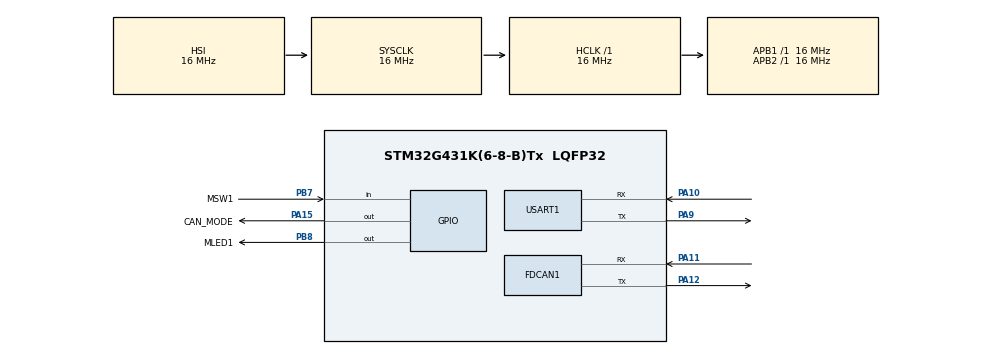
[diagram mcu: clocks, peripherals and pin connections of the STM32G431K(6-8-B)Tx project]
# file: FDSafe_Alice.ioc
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FDCAN1.CalculateBaudRateNominal=2000000
FDCAN1.CalculateTimeBitNominal=500
FDCAN1.CalculateTimeQuantumNominal=62.5
FDCAN1.DataSyncJumpWidth=2
FDCAN1.DataTimeSeg1=5
FDCAN1.DataTimeSeg2=2
FDCAN1.FrameFormat=FDCAN_FRAME_FD_NO_BRS
FDCAN1.NominalPrescaler=1
FDCAN1.NominalSyncJumpWidth=2
FDCAN1.NominalTimeSeg1=5
FDCAN1.NominalTimeSeg2=2
Mcu.Family=STM32G4
Mcu.Name=STM32G431K(6-8-B)Tx
Mcu.Package=LQFP32
NVIC.PriorityGroup=NVIC_PRIORITYGROUP_4
PA10.Mode=Asynchronous
PA10.Signal=USART1_RX
PA11.Mode=FDCAN_Activate
PA11.Signal=FDCAN1_RX
PA12.Mode=FDCAN_Activate
PA12.Signal=FDCAN1_TX
PA15.GPIO_Label=CAN_MODE
PA15.Signal=GPIO_Output
PA9.Mode=Asynchronous
PA9.Signal=USART1_TX
PB7.GPIO_Label=MSW1
PB7.GPIO_PuPd=GPIO_PULLUP
PB7.Signal=GPIO_Input
PB8-BOOT0.GPIO_Label=MLED1
PB8-BOOT0.PinState=GPIO_PIN_SET
PB8-BOOT0.Signal=GPIO_Output
ProjectManager.HeapSize=0x200
ProjectManager.StackSize=0x400
ProjectManager.TargetToolchain=STM32CubeIDE
RCC.AHBFreq_Value=16000000
RCC.APB1Freq_Value=16000000
RCC.APB1TimFreq_Value=16000000
RCC.APB2Freq_Value=16000000
RCC.APB2TimFreq_Value=16000000
RCC.CortexFreq_Value=16000000
RCC.EXTERNAL_CLOCK_VALUE=12288000
RCC.HCLKFreq_Value=16000000
RCC.HSE_VALUE=8000000
RCC.HSI48_VALUE=48000000
RCC.HSI_VALUE=16000000
RCC.LSE_VALUE=32768
RCC.PLLN=12
RCC.PLLQ=RCC_PLLQ_DIV4
RCC.SYSCLKFreq_VALUE=16000000
RCC.USBFreq_Value=48000000
RCC.VCOOutputFreq_Value=192000000
USART1.VirtualMode-Asynchronous=VM_ASYNC
VP_CRC_VS_CRC.Mode=CRC_Activate
VP_RNG_VS_RNG.Mode=RNG_Activate
VP_SYS_VS_DBSignals.Mode=DisableDeadBatterySignals
board=custom

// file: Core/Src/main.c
/* USER CODE BEGIN Header */
/**
 ******************************************************************************
 * @file           : main.c
 * @brief          : Main program body
 ******************************************************************************
 * @attention
 *
 * Copyright (c) 2024 STMicroelectronics.
 * All rights reserved.
 *
 * This software is licensed under terms that can be found in the LICENSE file
 * in the root directory of this software component.
 * If no LICENSE file comes with this software, it is provided AS-IS.
 *
 ******************************************************************************
 */
/* USER CODE END Header */
#include "main.h"

/* USER CODE BEGIN PD */

//#define PUTCHAR_PROTOTYPE int __io_putchar(int ch)
/* USER CODE END PD */

CRC_HandleTypeDef hcrc;

FDCAN_HandleTypeDef hfdcan1;

RNG_HandleTypeDef hrng;

UART_HandleTypeDef huart1;

void SystemClock_Config(void);
static void MX_GPIO_Init(void);
static void MX_FDCAN1_Init(void);
static void MX_USART1_UART_Init(void);
static void MX_RNG_Init(void);
static void MX_CRC_Init(void);

int main(void)
{

  /* MCU Configuration--------------------------------------------------------*/

  /* Reset of all peripherals, Initializes the Flash interface and the Systick. */
  HAL_Init();

  /* Configure the system clock */
  SystemClock_Config();

  /* Initialize all configured peripherals */
  MX_GPIO_Init();
  MX_FDCAN1_Init();
  MX_USART1_UART_Init();
  MX_RNG_Init();
  MX_CRC_Init();
  /* USER CODE BEGIN 2 */

	fdsafe_setup();

  /* USER CODE END 2 */

  /* Infinite loop */
  /* USER CODE BEGIN WHILE */
	while (1)
	{
		fdsafe_main();

    /* USER CODE END WHILE */

	}
}

void SystemClock_Config(void)
{
  RCC_OscInitTypeDef RCC_OscInitStruct = {0};
  RCC_ClkInitTypeDef RCC_ClkInitStruct = {0};

  /** Configure the main internal regulator output voltage
  */
  HAL_PWREx_ControlVoltageScaling(PWR_REGULATOR_VOLTAGE_SCALE1);

  /** Initializes the RCC Oscillators according to the specified parameters
  * in the RCC_OscInitTypeDef structure.
  */
  RCC_OscInitStruct.OscillatorType = RCC_OSCILLATORTYPE_HSI;
  RCC_OscInitStruct.HSIState = RCC_HSI_ON;
  RCC_OscInitStruct.HSICalibrationValue = RCC_HSICALIBRATION_DEFAULT;
  RCC_OscInitStruct.PLL.PLLState = RCC_PLL_ON;
  RCC_OscInitStruct.PLL.PLLSource = RCC_PLLSOURCE_HSI;
  RCC_OscInitStruct.PLL.PLLM = RCC_PLLM_DIV1;
  RCC_OscInitStruct.PLL.PLLN = 12;
  RCC_OscInitStruct.PLL.PLLP = RCC_PLLP_DIV2;
  RCC_OscInitStruct.PLL.PLLQ = RCC_PLLQ_DIV4;
  RCC_OscInitStruct.PLL.PLLR = RCC_PLLR_DIV2;
  if (HAL_RCC_OscConfig(&RCC_OscInitStruct) != HAL_OK)
  {
    Error_Handler();
  }

  /** Initializes the CPU, AHB and APB buses clocks
  */
  RCC_ClkInitStruct.ClockType = RCC_CLOCKTYPE_HCLK|RCC_CLOCKTYPE_SYSCLK
                              |RCC_CLOCKTYPE_PCLK1|RCC_CLOCKTYPE_PCLK2;
  RCC_ClkInitStruct.SYSCLKSource = RCC_SYSCLKSOURCE_HSI;
  RCC_ClkInitStruct.AHBCLKDivider = RCC_SYSCLK_DIV1;
  RCC_ClkInitStruct.APB1CLKDivider = RCC_HCLK_DIV1;
  RCC_ClkInitStruct.APB2CLKDivider = RCC_HCLK_DIV1;

  if (HAL_RCC_ClockConfig(&RCC_ClkInitStruct, FLASH_LATENCY_0) != HAL_OK)
  {
    Error_Handler();
  }
}

static void MX_CRC_Init(void)
{

  hcrc.Instance = CRC;
  hcrc.Init.DefaultPolynomialUse = DEFAULT_POLYNOMIAL_ENABLE;
  hcrc.Init.DefaultInitValueUse = DEFAULT_INIT_VALUE_ENABLE;
  hcrc.Init.InputDataInversionMode = CRC_INPUTDATA_INVERSION_NONE;
  hcrc.Init.OutputDataInversionMode = CRC_OUTPUTDATA_INVERSION_DISABLE;
  hcrc.InputDataFormat = CRC_INPUTDATA_FORMAT_BYTES;
  if (HAL_CRC_Init(&hcrc) != HAL_OK)
  {
    Error_Handler();
  }

}

static void MX_FDCAN1_Init(void)
{

  hfdcan1.Instance = FDCAN1;
  hfdcan1.Init.ClockDivider = FDCAN_CLOCK_DIV1;
  hfdcan1.Init.FrameFormat = FDCAN_FRAME_FD_NO_BRS;
  hfdcan1.Init.Mode = FDCAN_MODE_NORMAL;
  hfdcan1.Init.AutoRetransmission = DISABLE;
  hfdcan1.Init.TransmitPause = DISABLE;
  hfdcan1.Init.ProtocolException = DISABLE;
  hfdcan1.Init.NominalPrescaler = 1;
  hfdcan1.Init.NominalSyncJumpWidth = 2;
  hfdcan1.Init.NominalTimeSeg1 = 5;
  hfdcan1.Init.NominalTimeSeg2 = 2;
  hfdcan1.Init.DataPrescaler = 1;
  hfdcan1.Init.DataSyncJumpWidth = 2;
  hfdcan1.Init.DataTimeSeg1 = 5;
  hfdcan1.Init.DataTimeSeg2 = 2;
  hfdcan1.Init.StdFiltersNbr = 0;
  hfdcan1.Init.ExtFiltersNbr = 0;
  hfdcan1.Init.TxFifoQueueMode = FDCAN_TX_FIFO_OPERATION;
  if (HAL_FDCAN_Init(&hfdcan1) != HAL_OK)
  {
    Error_Handler();
  }

}

static void MX_RNG_Init(void)
{

  hrng.Instance = RNG;
  hrng.Init.ClockErrorDetection = RNG_CED_ENABLE;
  if (HAL_RNG_Init(&hrng) != HAL_OK)
  {
    Error_Handler();
  }

}

static void MX_USART1_UART_Init(void)
{

  huart1.Instance = USART1;
  huart1.Init.BaudRate = 115200;
  huart1.Init.WordLength = UART_WORDLENGTH_8B;
  huart1.Init.StopBits = UART_STOPBITS_1;
  huart1.Init.Parity = UART_PARITY_NONE;
  huart1.Init.Mode = UART_MODE_TX_RX;
  huart1.Init.HwFlowCtl = UART_HWCONTROL_NONE;
  huart1.Init.OverSampling = UART_OVERSAMPLING_16;
  huart1.Init.OneBitSampling = UART_ONE_BIT_SAMPLE_DISABLE;
  huart1.Init.ClockPrescaler = UART_PRESCALER_DIV1;
  huart1.AdvancedInit.AdvFeatureInit = UART_ADVFEATURE_NO_INIT;
  if (HAL_UART_Init(&huart1) != HAL_OK)
  {
    Error_Handler();
  }
  if (HAL_UARTEx_SetTxFifoThreshold(&huart1, UART_TXFIFO_THRESHOLD_1_8) != HAL_OK)
  {
    Error_Handler();
  }
  if (HAL_UARTEx_SetRxFifoThreshold(&huart1, UART_RXFIFO_THRESHOLD_1_8) != HAL_OK)
  {
    Error_Handler();
  }
  if (HAL_UARTEx_DisableFifoMode(&huart1) != HAL_OK)
  {
    Error_Handler();
  }

}

static void MX_GPIO_Init(void)
{
  GPIO_InitTypeDef GPIO_InitStruct = {0};

  /* GPIO Ports Clock Enable */
  __HAL_RCC_GPIOA_CLK_ENABLE();
  __HAL_RCC_GPIOB_CLK_ENABLE();

  /*Configure GPIO pin Output Level */
  HAL_GPIO_WritePin(CAN_MODE_GPIO_Port, CAN_MODE_Pin, GPIO_PIN_RESET);

  /*Configure GPIO pin Output Level */
  HAL_GPIO_WritePin(MLED1_GPIO_Port, MLED1_Pin, GPIO_PIN_SET);

  /*Configure GPIO pin : CAN_MODE_Pin */
  GPIO_InitStruct.Pin = CAN_MODE_Pin;
  GPIO_InitStruct.Mode = GPIO_MODE_OUTPUT_PP;
  GPIO_InitStruct.Pull = GPIO_NOPULL;
  GPIO_InitStruct.Speed = GPIO_SPEED_FREQ_LOW;
  HAL_GPIO_Init(CAN_MODE_GPIO_Port, &GPIO_InitStruct);

  /*Configure GPIO pin : MSW1_Pin */
  GPIO_InitStruct.Pin = MSW1_Pin;
  GPIO_InitStruct.Mode = GPIO_MODE_INPUT;
  GPIO_InitStruct.Pull = GPIO_PULLUP;
  HAL_GPIO_Init(MSW1_GPIO_Port, &GPIO_InitStruct);

  /*Configure GPIO pin : MLED1_Pin */
  GPIO_InitStruct.Pin = MLED1_Pin;
  GPIO_InitStruct.Mode = GPIO_MODE_OUTPUT_PP;
  GPIO_InitStruct.Pull = GPIO_NOPULL;
  GPIO_InitStruct.Speed = GPIO_SPEED_FREQ_LOW;
  HAL_GPIO_Init(MLED1_GPIO_Port, &GPIO_InitStruct);

}

void Error_Handler(void)
{
	__disable_irq();
	while (1)
	{
	}
}
